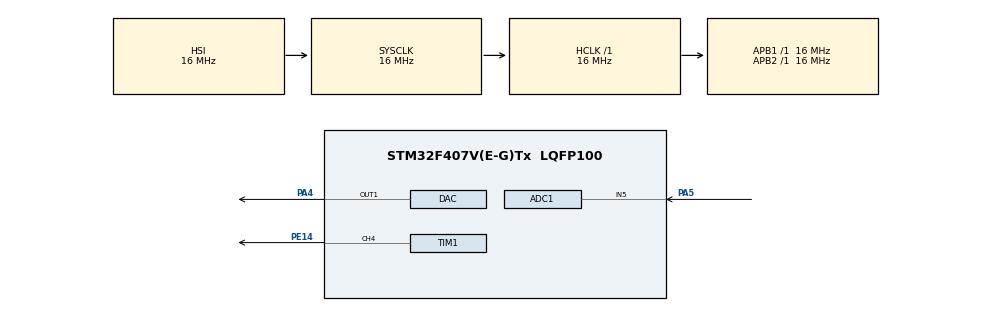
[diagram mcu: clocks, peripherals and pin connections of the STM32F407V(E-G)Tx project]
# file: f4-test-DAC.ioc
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ADC1.Channel-2\#ChannelRegularConversion=ADC_CHANNEL_5
ADC1.EOCSelection=ADC_EOC_SEQ_CONV
ADC1.NbrOfConversionFlag=1
ADC1.Rank-2\#ChannelRegularConversion=1
ADC1.Resolution=ADC_RESOLUTION_8B
ADC1.SamplingTime-2\#ChannelRegularConversion=ADC_SAMPLETIME_3CYCLES
ADC1.ScanConvMode=DISABLE
ADC1.master=1
DAC.DAC_OutputBuffer=DAC_OUTPUTBUFFER_DISABLE
DAC.DAC_Trigger=DAC_TRIGGER_T6_TRGO
DAC.WaveGeneration=DISABLE
Dma.DAC1.0.Direction=DMA_MEMORY_TO_PERIPH
Dma.DAC1.0.FIFOMode=DMA_FIFOMODE_DISABLE
Dma.DAC1.0.Instance=DMA1_Stream5
Dma.DAC1.0.MemDataAlignment=DMA_MDATAALIGN_HALFWORD
Dma.DAC1.0.MemInc=DMA_MINC_ENABLE
Dma.DAC1.0.Mode=DMA_CIRCULAR
Dma.DAC1.0.PeriphDataAlignment=DMA_PDATAALIGN_HALFWORD
Dma.DAC1.0.PeriphInc=DMA_PINC_DISABLE
Dma.DAC1.0.Priority=DMA_PRIORITY_LOW
Dma.Request0=DAC1
Dma.Request1=TIM1_CH4/TRIG/COM
Dma.TIM1_CH4/TRIG/COM.1.Direction=DMA_MEMORY_TO_PERIPH
Dma.TIM1_CH4/TRIG/COM.1.FIFOMode=DMA_FIFOMODE_DISABLE
Dma.TIM1_CH4/TRIG/COM.1.Instance=DMA2_Stream4
Dma.TIM1_CH4/TRIG/COM.1.MemDataAlignment=DMA_MDATAALIGN_HALFWORD
Dma.TIM1_CH4/TRIG/COM.1.MemInc=DMA_MINC_ENABLE
Dma.TIM1_CH4/TRIG/COM.1.Mode=DMA_CIRCULAR
Dma.TIM1_CH4/TRIG/COM.1.PeriphDataAlignment=DMA_PDATAALIGN_HALFWORD
Dma.TIM1_CH4/TRIG/COM.1.PeriphInc=DMA_PINC_DISABLE
Dma.TIM1_CH4/TRIG/COM.1.Priority=DMA_PRIORITY_LOW
Mcu.Family=STM32F4
Mcu.Name=STM32F407V(E-G)Tx
Mcu.Package=LQFP100
NVIC.DMA1_Stream5_IRQn=true\:0\:0\:false\:false\:true\:false\:true\:true
NVIC.DMA2_Stream4_IRQn=true\:0\:0\:false\:false\:true\:false\:true\:true
NVIC.PriorityGroup=NVIC_PRIORITYGROUP_4
PA4.Signal=COMP_DAC1_group
PA5.Signal=ADCx_IN5
PE14.Signal=S_TIM1_CH4
ProjectManager.HeapSize=0x200
ProjectManager.StackSize=0x400
ProjectManager.TargetToolchain=STM32CubeIDE
RCC.AHBFreq_Value=16000000
RCC.APB1Freq_Value=16000000
RCC.APB2Freq_Value=16000000
RCC.CortexFreq_Value=16000000
RCC.HSE_VALUE=25000000
RCC.HSI_VALUE=16000000
RCC.LSE_VALUE=32768
RCC.SYSCLKFreq_VALUE=16000000
RCC.VCOOutputFreq_Value=192000000
SH.ADCx_IN5.0=ADC1_IN5,IN5
SH.COMP_DAC1_group.0=DAC_OUT1,DAC_OUT1
SH.S_TIM1_CH4.0=TIM1_CH4,PWM Generation4 CH4
TIM1.Channel-PWM\ Generation4\ CH4=TIM_CHANNEL_4
TIM1.OCFastMode_PWM-PWM\ Generation4\ CH4=TIM_OCFAST_DISABLE
TIM1.Period=255
TIM1.Prescaler=1
TIM6.Period=31
TIM6.Prescaler=255
TIM6.TIM_MasterOutputTrigger=TIM_TRGO_UPDATE
VP_TIM1_VS_ClockSourceINT.Mode=Internal
VP_TIM6_VS_ClockSourceINT.Mode=Enable_Timer
board=custom

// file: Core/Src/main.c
/* USER CODE BEGIN Header */
/**
  ******************************************************************************
  * @file           : main.c
  * @brief          : Main program body
  ******************************************************************************
  * @attention
  *
  * Copyright (c) 2026 STMicroelectronics.
  * All rights reserved.
  *
  * This software is licensed under terms that can be found in the LICENSE file
  * in the root directory of this software component.
  * If no LICENSE file comes with this software, it is provided AS-IS.
  *
  ******************************************************************************
  */
/* USER CODE END Header */
#include "main.h"

/* USER CODE BEGIN PTD */
#define SINE_SAMPLES 32
/* USER CODE END PTD */

ADC_HandleTypeDef hadc1;

DAC_HandleTypeDef hdac;
DMA_HandleTypeDef hdma_dac1;

TIM_HandleTypeDef htim1;
TIM_HandleTypeDef htim6;
DMA_HandleTypeDef hdma_tim1_ch4_trig_com;

/* USER CODE BEGIN PV */
uint16_t adcValue =0;
/* USER CODE END PV */

void SystemClock_Config(void);
static void MX_GPIO_Init(void);
static void MX_DMA_Init(void);
static void MX_DAC_Init(void);
static void MX_TIM6_Init(void);
static void MX_TIM1_Init(void);
static void MX_ADC1_Init(void);

int main(void)
{

  /* MCU Configuration--------------------------------------------------------*/

  /* Reset of all peripherals, Initializes the Flash interface and the Systick. */
  HAL_Init();

  /* Configure the system clock */
  SystemClock_Config();

  /* Initialize all configured peripherals */
  MX_GPIO_Init();
  MX_DMA_Init();
  MX_DAC_Init();
  MX_TIM6_Init();
  MX_TIM1_Init();
  MX_ADC1_Init();
  /* USER CODE BEGIN 2 */

  // Start DAC
  //HAL_DAC_Start(&hdac, DAC_CHANNEL_1);

// sine test
//  const uint16_t sine_table[SINE_SAMPLES] =
//  {
//  2048, 2447, 2831, 3185, 3495, 3750, 3939, 4056,
//  4095, 4056, 3939, 3750, 3495, 3185, 2831, 2447,
//  2048, 1649, 1265,  911,  601,  346,  157,   40,
//  0,    40,   157,  346,  601,  911, 1265, 1649
//  };

  // Start DAC with DMA
//  HAL_DAC_Start_DMA(&hdac,
//                    DAC_CHANNEL_1,
//                    (uint32_t*)sine_table,
//                    SINE_SAMPLES,
//                    DAC_ALIGN_12B_R);

  // Start TIM6 (this triggers DAC updates)
//  HAL_TIM_Base_Start(&htim6);

  //__HAL_TIM_SET_COMPARE(&htim1, TIM_CHANNEL_4, 250);

  //sine test
//  HAL_TIM_PWM_Start_DMA(&htim1, TIM_CHANNEL_4, (uint32_t*)sine_table, SINE_SAMPLES);

  HAL_TIM_PWM_Start(&htim1,TIM_CHANNEL_4);
  __HAL_TIM_SET_COMPARE(&htim1, TIM_CHANNEL_4, 250);
  HAL_TIM_Base_Start(&htim6);
  HAL_DAC_Start(&hdac, DAC_CHANNEL_1);
  HAL_ADC_Start(&hadc1);

  /* USER CODE END 2 */

  /* Infinite loop */
  /* USER CODE BEGIN WHILE */
  while (1)
  {

	  HAL_ADC_Start(&hadc1);
	  if (HAL_ADC_PollForConversion(&hadc1, HAL_MAX_DELAY) == HAL_OK)
	  {
		  // Read the ADC Value
		  adcValue = HAL_ADC_GetValue(&hadc1);
		  HAL_DAC_SetValue(&hdac, DAC1_CHANNEL_1, DAC_ALIGN_8B_R, adcValue);
		  __HAL_TIM_SET_COMPARE(&htim1, TIM_CHANNEL_4, adcValue);
	  }
	  HAL_ADC_Stop(&hadc1);

	  //HAL_ADC_PollForConversion(&hadc1, 100);

	  // software table defined sinewave
//	    for (int i = 0; i < 32; i++)
//	    {
//	        HAL_DAC_SetValue(&hdac,
//	                         DAC_CHANNEL_1,
//	                         DAC_ALIGN_12B_R,
//	                         sine_table[i]);
//
//	        HAL_Delay(1);
//	    }
    /* USER CODE END WHILE */

  }
}

void SystemClock_Config(void)
{
  RCC_OscInitTypeDef RCC_OscInitStruct = {0};
  RCC_ClkInitTypeDef RCC_ClkInitStruct = {0};

  /** Configure the main internal regulator output voltage
  */
  __HAL_RCC_PWR_CLK_ENABLE();
  __HAL_PWR_VOLTAGESCALING_CONFIG(PWR_REGULATOR_VOLTAGE_SCALE1);

  /** Initializes the RCC Oscillators according to the specified parameters
  * in the RCC_OscInitTypeDef structure.
  */
  RCC_OscInitStruct.OscillatorType = RCC_OSCILLATORTYPE_HSI;
  RCC_OscInitStruct.HSIState = RCC_HSI_ON;
  RCC_OscInitStruct.HSICalibrationValue = RCC_HSICALIBRATION_DEFAULT;
  RCC_OscInitStruct.PLL.PLLState = RCC_PLL_NONE;
  if (HAL_RCC_OscConfig(&RCC_OscInitStruct) != HAL_OK)
  {
    Error_Handler();
  }

  /** Initializes the CPU, AHB and APB buses clocks
  */
  RCC_ClkInitStruct.ClockType = RCC_CLOCKTYPE_HCLK|RCC_CLOCKTYPE_SYSCLK
                              |RCC_CLOCKTYPE_PCLK1|RCC_CLOCKTYPE_PCLK2;
  RCC_ClkInitStruct.SYSCLKSource = RCC_SYSCLKSOURCE_HSI;
  RCC_ClkInitStruct.AHBCLKDivider = RCC_SYSCLK_DIV1;
  RCC_ClkInitStruct.APB1CLKDivider = RCC_HCLK_DIV1;
  RCC_ClkInitStruct.APB2CLKDivider = RCC_HCLK_DIV1;

  if (HAL_RCC_ClockConfig(&RCC_ClkInitStruct, FLASH_LATENCY_0) != HAL_OK)
  {
    Error_Handler();
  }
}

static void MX_ADC1_Init(void)
{

  ADC_ChannelConfTypeDef sConfig = {0};

  /** Configure the global features of the ADC (Clock, Resolution, Data Alignment and number of conversion)
  */
  hadc1.Instance = ADC1;
  hadc1.Init.ClockPrescaler = ADC_CLOCK_SYNC_PCLK_DIV2;
  hadc1.Init.Resolution = ADC_RESOLUTION_8B;
  hadc1.Init.ScanConvMode = DISABLE;
  hadc1.Init.ContinuousConvMode = DISABLE;
  hadc1.Init.DiscontinuousConvMode = DISABLE;
  hadc1.Init.ExternalTrigConvEdge = ADC_EXTERNALTRIGCONVEDGE_NONE;
  hadc1.Init.ExternalTrigConv = ADC_SOFTWARE_START;
  hadc1.Init.DataAlign = ADC_DATAALIGN_RIGHT;
  hadc1.Init.NbrOfConversion = 1;
  hadc1.Init.DMAContinuousRequests = DISABLE;
  hadc1.Init.EOCSelection = ADC_EOC_SEQ_CONV;
  if (HAL_ADC_Init(&hadc1) != HAL_OK)
  {
    Error_Handler();
  }

  /** Configure for the selected ADC regular channel its corresponding rank in the sequencer and its sample time.
  */
  sConfig.Channel = ADC_CHANNEL_5;
  sConfig.Rank = 1;
  sConfig.SamplingTime = ADC_SAMPLETIME_3CYCLES;
  if (HAL_ADC_ConfigChannel(&hadc1, &sConfig) != HAL_OK)
  {
    Error_Handler();
  }

}

static void MX_DAC_Init(void)
{

  DAC_ChannelConfTypeDef sConfig = {0};

  /** DAC Initialization
  */
  hdac.Instance = DAC;
  if (HAL_DAC_Init(&hdac) != HAL_OK)
  {
    Error_Handler();
  }

  /** DAC channel OUT1 config
  */
  sConfig.DAC_Trigger = DAC_TRIGGER_T6_TRGO;
  sConfig.DAC_OutputBuffer = DAC_OUTPUTBUFFER_DISABLE;
  if (HAL_DAC_ConfigChannel(&hdac, &sConfig, DAC_CHANNEL_1) != HAL_OK)
  {
    Error_Handler();
  }

}

static void MX_TIM1_Init(void)
{

  TIM_ClockConfigTypeDef sClockSourceConfig = {0};
  TIM_MasterConfigTypeDef sMasterConfig = {0};
  TIM_OC_InitTypeDef sConfigOC = {0};
  TIM_BreakDeadTimeConfigTypeDef sBreakDeadTimeConfig = {0};

  htim1.Instance = TIM1;
  htim1.Init.Prescaler = 1;
  htim1.Init.CounterMode = TIM_COUNTERMODE_UP;
  htim1.Init.Period = 255;
  htim1.Init.ClockDivision = TIM_CLOCKDIVISION_DIV1;
  htim1.Init.RepetitionCounter = 0;
  htim1.Init.AutoReloadPreload = TIM_AUTORELOAD_PRELOAD_DISABLE;
  if (HAL_TIM_Base_Init(&htim1) != HAL_OK)
  {
    Error_Handler();
  }
  sClockSourceConfig.ClockSource = TIM_CLOCKSOURCE_INTERNAL;
  if (HAL_TIM_ConfigClockSource(&htim1, &sClockSourceConfig) != HAL_OK)
  {
    Error_Handler();
  }
  if (HAL_TIM_PWM_Init(&htim1) != HAL_OK)
  {
    Error_Handler();
  }
  sMasterConfig.MasterOutputTrigger = TIM_TRGO_RESET;
  sMasterConfig.MasterSlaveMode = TIM_MASTERSLAVEMODE_DISABLE;
  if (HAL_TIMEx_MasterConfigSynchronization(&htim1, &sMasterConfig) != HAL_OK)
  {
    Error_Handler();
  }
  sConfigOC.OCMode = TIM_OCMODE_PWM1;
  sConfigOC.Pulse = 0;
  sConfigOC.OCPolarity = TIM_OCPOLARITY_HIGH;
  sConfigOC.OCFastMode = TIM_OCFAST_DISABLE;
  sConfigOC.OCIdleState = TIM_OCIDLESTATE_RESET;
  sConfigOC.OCNIdleState = TIM_OCNIDLESTATE_RESET;
  if (HAL_TIM_PWM_ConfigChannel(&htim1, &sConfigOC, TIM_CHANNEL_4) != HAL_OK)
  {
    Error_Handler();
  }
  sBreakDeadTimeConfig.OffStateRunMode = TIM_OSSR_DISABLE;
  sBreakDeadTimeConfig.OffStateIDLEMode = TIM_OSSI_DISABLE;
  sBreakDeadTimeConfig.LockLevel = TIM_LOCKLEVEL_OFF;
  sBreakDeadTimeConfig.DeadTime = 0;
  sBreakDeadTimeConfig.BreakState = TIM_BREAK_DISABLE;
  sBreakDeadTimeConfig.BreakPolarity = TIM_BREAKPOLARITY_HIGH;
  sBreakDeadTimeConfig.AutomaticOutput = TIM_AUTOMATICOUTPUT_DISABLE;
  if (HAL_TIMEx_ConfigBreakDeadTime(&htim1, &sBreakDeadTimeConfig) != HAL_OK)
  {
    Error_Handler();
  }
  HAL_TIM_MspPostInit(&htim1);

}

static void MX_TIM6_Init(void)
{

  TIM_MasterConfigTypeDef sMasterConfig = {0};

  htim6.Instance = TIM6;
  htim6.Init.Prescaler = 255;
  htim6.Init.CounterMode = TIM_COUNTERMODE_UP;
  htim6.Init.Period = 31;
  htim6.Init.AutoReloadPreload = TIM_AUTORELOAD_PRELOAD_DISABLE;
  if (HAL_TIM_Base_Init(&htim6) != HAL_OK)
  {
    Error_Handler();
  }
  sMasterConfig.MasterOutputTrigger = TIM_TRGO_UPDATE;
  sMasterConfig.MasterSlaveMode = TIM_MASTERSLAVEMODE_DISABLE;
  if (HAL_TIMEx_MasterConfigSynchronization(&htim6, &sMasterConfig) != HAL_OK)
  {
    Error_Handler();
  }

}

static void MX_DMA_Init(void)
{

  /* DMA controller clock enable */
  __HAL_RCC_DMA1_CLK_ENABLE();
  __HAL_RCC_DMA2_CLK_ENABLE();

  /* DMA interrupt init */
  /* DMA1_Stream5_IRQn interrupt configuration */
  HAL_NVIC_SetPriority(DMA1_Stream5_IRQn, 0, 0);
  HAL_NVIC_EnableIRQ(DMA1_Stream5_IRQn);
  /* DMA2_Stream4_IRQn interrupt configuration */
  HAL_NVIC_SetPriority(DMA2_Stream4_IRQn, 0, 0);
  HAL_NVIC_EnableIRQ(DMA2_Stream4_IRQn);

}

static void MX_GPIO_Init(void)
{

  /* GPIO Ports Clock Enable */
  __HAL_RCC_GPIOA_CLK_ENABLE();
  __HAL_RCC_GPIOE_CLK_ENABLE();

}

void Error_Handler(void)
{
  __disable_irq();
  while (1)
  {
  }
}
